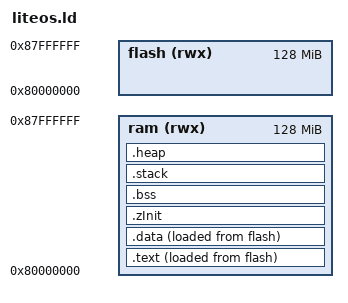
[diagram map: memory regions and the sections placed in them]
 /*
 * Copyright (c) 2013-2019 Huawei Technologies Co., Ltd. All rights reserved.
 * Copyright (c) 2020-2022 Huawei Device Co., Ltd. All rights reserved.
 *
 * Redistribution and use in source and binary forms, with or without modification,
 * are permitted provided that the following conditions are met:
 *
 * 1. Redistributions of source code must retain the above copyright notice, this list of
 *    conditions and the following disclaimer.
 *
 * 2. Redistributions in binary form must reproduce the above copyright notice, this list
 *    of conditions and the following disclaimer in the documentation and/or other materials
 *    provided with the distribution.
 *
 * 3. Neither the name of the copyright holder nor the names of its contributors may be used
 *    to endorse or promote products derived from this software without specific prior written
 *    permission.
 *
 * THIS SOFTWARE IS PROVIDED BY THE COPYRIGHT HOLDERS AND CONTRIBUTORS
 * "AS IS" AND ANY EXPRESS OR IMPLIED WARRANTIES, INCLUDING, BUT NOT LIMITED TO,
 * THE IMPLIED WARRANTIES OF MERCHANTABILITY AND FITNESS FOR A PARTICULAR
 * PURPOSE ARE DISCLAIMED. IN NO EVENT SHALL THE COPYRIGHT HOLDER OR
 * CONTRIBUTORS BE LIABLE FOR ANY DIRECT, INDIRECT, INCIDENTAL, SPECIAL,
 * EXEMPLARY, OR CONSEQUENTIAL DAMAGES (INCLUDING, BUT NOT LIMITED TO,
 * PROCUREMENT OF SUBSTITUTE GOODS OR SERVICES; LOSS OF USE, DATA, OR PROFITS;
 * OR BUSINESS INTERRUPTION) HOWEVER CAUSED AND ON ANY THEORY OF LIABILITY,
 * WHETHER IN CONTRACT, STRICT LIABILITY, OR TORT (INCLUDING NEGLIGENCE OR
 * OTHERWISE) ARISING IN ANY WAY OUT OF THE USE OF THIS SOFTWARE, EVEN IF
 * ADVISED OF THE POSSIBILITY OF SUCH DAMAGE.
 */

OUTPUT_FORMAT("elf32-littleriscv", "elf32-littleriscv", "elf32-littleriscv")
OUTPUT_ARCH("riscv")
ENTRY(_start)

RAM_ADDR_START            = 0x80000000;
RAM_ADDR_SIZE             = 128M;
FLASH_LOAD_START          = RAM_ADDR_START;
FLASH_LOAD_SIZE           = RAM_ADDR_SIZE;
EXCEPT_STACK_SIZE         = 2K;
NMI_STACK_SIZE            = 1K;
START_AND_IRQ_STACK_SIZE  = 8K;

MEMORY
{
   ram(rwx) : ORIGIN = RAM_ADDR_START, LENGTH = RAM_ADDR_SIZE
   flash(rwx) : ORIGIN = FLASH_LOAD_START, LENGTH = FLASH_LOAD_SIZE
}
SECTIONS
{
  .text : ALIGN(0x20)
  {
    __text_start = .;
    . = ALIGN(0x10);
    *(.start.text)
    *(.interrupt.*)
    *(.text .text.*)
    . = ALIGN(0x20);
    __rodata_start = .;
    . = ALIGN(0x10);
    *(.rodata .rodata.* .srodata .srodata.*)
    . = ALIGN(0x20);
    __text_end = .;
    _hdf_drivers_start = .;
    KEEP(*(.hdf.driver))
    _hdf_drivers_end = .;
  } > ram AT > flash
  .data : ALIGN(0x20)
  {
    __global_pointer$ = . + 0x800;
    __data_load_start = LOADADDR(.data);
    __data_start = .;
    /* preinit_array */
    . = ALIGN(4);
    PROVIDE_HIDDEN (__preinit_array_start = .);
    KEEP (*(.preinit_array))
    PROVIDE_HIDDEN (__preinit_array_end = .);
    /* init_array */
    . = ALIGN(4);
    PROVIDE_HIDDEN (__init_array_start = .);
    KEEP (*(SORT_BY_INIT_PRIORITY(.init_array.*)))
    KEEP (*(.init_array))
    PROVIDE_HIDDEN (__init_array_end = .);
    /* fini_array */
    . = ALIGN(4);
    PROVIDE_HIDDEN (__fini_array_start = .);
    KEEP (*(SORT_BY_INIT_PRIORITY(.fini_array.*)))
    KEEP (*(.fini_array))
    PROVIDE_HIDDEN (__fini_array_end = .);
    . = ALIGN(0x10);
    *(.data .data.* .sdata .sdata.*)
    . = ALIGN(0x20);
    __data_end = .;
    _edata = .;
  } > ram AT > flash
  __data_load_size = SIZEOF(.data);
  /* zInit code and data - will be freed after init */
  .zInit (.) :
  {
    __zinitcall_bsp_start = .;
    KEEP (*(.zinitcall.bsp0.init))
    KEEP (*(.zinitcall.bsp1.init))
    KEEP (*(.zinitcall.bsp2.init))
    KEEP (*(.zinitcall.bsp3.init))
    KEEP (*(.zinitcall.bsp4.init))
    __zinitcall_bsp_end = .;
    . = ALIGN(4);
    __zinitcall_device_start = .;
    KEEP (*(.zinitcall.device0.init))
    KEEP (*(.zinitcall.device1.init))
    KEEP (*(.zinitcall.device2.init))
    KEEP (*(.zinitcall.device3.init))
    KEEP (*(.zinitcall.device4.init))
    __zinitcall_device_end = .;
    . = ALIGN(4);
    __zinitcall_core_start = .;
    KEEP (*(.zinitcall.core0.init))
    KEEP (*(.zinitcall.core1.init))
    KEEP (*(.zinitcall.core2.init))
    KEEP (*(.zinitcall.core3.init))
    KEEP (*(.zinitcall.core4.init))
    __zinitcall_core_end = .;
    . = ALIGN(4);
    __zinitcall_sys_service_start = .;
    KEEP (*(.zinitcall.sys.service0.init))
    KEEP (*(.zinitcall.sys.service1.init))
    KEEP (*(.zinitcall.sys.service2.init))
    KEEP (*(.zinitcall.sys.service3.init))
    KEEP (*(.zinitcall.sys.service4.init))
    __zinitcall_sys_service_end = .;
    . = ALIGN(4);
    __zinitcall_sys_feature_start = .;
    KEEP (*(.zinitcall.sys.feature0.init))
    KEEP (*(.zinitcall.sys.feature1.init))
    KEEP (*(.zinitcall.sys.feature2.init))
    KEEP (*(.zinitcall.sys.feature3.init))
    KEEP (*(.zinitcall.sys.feature4.init))
    __zinitcall_sys_feature_end = .;
    . = ALIGN(4);
    __zinitcall_run_start = .;
    KEEP (*(.zinitcall.run0.init))
    KEEP (*(.zinitcall.run1.init))
    KEEP (*(.zinitcall.run2.init))
    KEEP (*(.zinitcall.run3.init))
    KEEP (*(.zinitcall.run4.init))
    __zinitcall_run_end = .;
    . = ALIGN(4);
    __zinitcall_app_service_start = .;
    KEEP (*(.zinitcall.app.service0.init))
    KEEP (*(.zinitcall.app.service1.init))
    KEEP (*(.zinitcall.app.service2.init))
    KEEP (*(.zinitcall.app.service3.init))
    KEEP (*(.zinitcall.app.service4.init))
    __zinitcall_app_service_end = .;
    . = ALIGN(4);
    __zinitcall_app_feature_start = .;
    KEEP (*(.zinitcall.app.feature0.init))
    KEEP (*(.zinitcall.app.feature1.init))
    KEEP (*(.zinitcall.app.feature2.init))
    KEEP (*(.zinitcall.app.feature3.init))
    KEEP (*(.zinitcall.app.feature4.init))
    __zinitcall_app_feature_end = .;
    . = ALIGN(4);
    __zinitcall_test_start = .;
    KEEP (*(.zinitcall.test0.init))
    KEEP (*(.zinitcall.test1.init))
    KEEP (*(.zinitcall.test2.init))
    KEEP (*(.zinitcall.test3.init))
    KEEP (*(.zinitcall.test4.init))
    __zinitcall_test_end = .;
    . = ALIGN(4);
    __zinitcall_exit_start = .;
    KEEP (*(.zinitcall.exit0.init))
    KEEP (*(.zinitcall.exit1.init))
    KEEP (*(.zinitcall.exit2.init))
    KEEP (*(.zinitcall.exit3.init))
    KEEP (*(.zinitcall.exit4.init))
    __zinitcall_exit_end = .;
    . = ALIGN(4);
  } > ram
  .bss (NOLOAD): ALIGN(0x20)
  {
    __bss_start = .;
    . = ALIGN(0x10);
    *(.kernel.bss*)
    *(.bss.* .sbss.*)
    . = ALIGN(0x20);
    __bss_end = .;
  } > ram
  .stack (NOLOAD): ALIGN(0x40)
  {
    __stack_bootom = .;
    . += EXCEPT_STACK_SIZE;
    __except_stack_top = .;
    . += START_AND_IRQ_STACK_SIZE;
    __start_and_irq_stack_top = .;
  } > ram

  .heap (NOLOAD): ALIGN(0x40)
  {
    __heap_start = .;
  } > ram

  __heap_size = RAM_ADDR_SIZE - (__heap_start - __text_start);
  _end = .;
  end = .;
}
